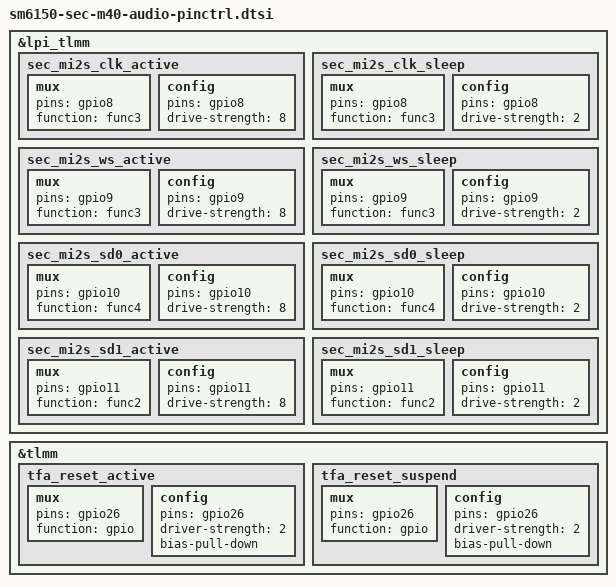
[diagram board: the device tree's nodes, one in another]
&lpi_tlmm  {
	sec_mi2s_clk_active: sec_mi2s_clk_active {
		mux {
			pins = "gpio8";
			function = "func3";
		};
		config {
			pins = "gpio8";
			drive-strength = <8>;
		};
	};
	sec_mi2s_clk_sleep: sec_mi2s_clk_sleep {
		mux {
			pins = "gpio8";
			function = "func3";
		};
		config {
			pins = "gpio8";
			drive-strength = <2>;
		};
	};

	sec_mi2s_ws_active: sec_mi2s_ws_active {
		mux {
			pins = "gpio9";
			function = "func3";
		};
		config {
			pins = "gpio9";
			drive-strength = <8>;
		};
	};

	sec_mi2s_ws_sleep: sec_mi2s_ws_sleep {
		mux {
			pins = "gpio9";
			function = "func3";
		};
		config {
			pins = "gpio9";
			drive-strength = <2>;
		};
	};

	sec_mi2s_sd0_active: sec_mi2s_sd0_active {
		mux {
			pins = "gpio10";
			function = "func4";
		};

		config {
			pins = "gpio10";
			drive-strength = <8>;
		};
	};

	sec_mi2s_sd0_sleep: sec_mi2s_sd0_sleep {
		mux {
			pins = "gpio10";
			function = "func4";
		};
		config {
			pins = "gpio10";
			drive-strength = <2>;
		};
	};

	sec_mi2s_sd1_active: sec_mi2s_sd1_active {
		mux {
			pins = "gpio11";
			function = "func2";
		};
		config {
			pins = "gpio11";
			drive-strength = <8>;
		};
	};

	sec_mi2s_sd1_sleep: sec_mi2s_sd1_sleep {
		mux {
			pins = "gpio11";
			function = "func2";
		};
		config {
			pins = "gpio11";
			drive-strength = <2>;
		};
	};
};

&tlmm {
	tfa_reset_active: tfa_reset_active{
		mux {
			pins = "gpio26";
			function = "gpio";		
		};
		config {
			pins = "gpio26";
			driver-strength = <2>;
			bias-pull-down;			
		};	
	};

	tfa_reset_suspend: tfa_reset_suspend{
		mux {
			pins = "gpio26";
			function = "gpio";		
		};
		config {
			pins = "gpio26";
			driver-strength = <2>;
			bias-pull-down;			
		};	
	};

};
